# LAN9255ZMX019 device description
Architecture: CORTEX-M4; Family: LAN9255; Series: LAN9255ZMX
Registers are 32-bit, read-write, reset 0x0 unless marked. A register's access mark holds for its fields unless they carry their own. Offsets are from the block's base; [hi:lo] are bit positions; {n}, {i} and the like mark numbered series; 'fields as' and 'values as' point back to an identical list.

## Pinouts (pin number, pad)
TQFP128: 1 OSCO, 2 PB03, 3 PA00, 4 OSCVDD12, 5 PA01, 6 OSCVSS, 7 VDD33, 8 PA02, 9 PA03, 10 PB04, 11 PB05, 12 VDDCR1, 13 REG_EN, 14 CLK25_EN, 15 GNDANA, 16 VDDANA, 17 ERRLED_LEDPOL4, 18 WAIT_ACK, 19 PB06, 20 PB07, 21 RSTN, 22 PB08, 23 PB09, 24 SIO2, 25 PA04, 26 SIO1, 27 PA05, 28 PA06, 29 VDDIO1_L, 30 PA07, 31 GPIO8, 32 GPIO7, 33 PA08, 34 PA09, 35 PA10, 36 PA11, 37 VDDIOB, 38 SIO0, 39 SYNC1_LATCH1, 40 PB10, 41 SPICLK, 42 PB11, 43 PB12, 44 PB13, 45 VDDIO2_L, 46 PB14, 47 PB15, 48 NC, 49 GPIO6, 50 GPIO5, 51 GPIO4, 52 VDDCR2, 53 EEEMULSPI2, 54 GPIO11, 55 GPIO12, 56 GPIO13, 57 GPIO10, 58 GPIO14, 59 GPIO15, 60 VDDIO3_L, 61 PA12, 62 PA13, 63 PA14, 64 PA15, 65 VDDIO1_S, 66 GPIO9, 67 PA16, 68 PA17, 69 PA18, 70 SYNC0_LATCH0, 71 SIO3, 72 GPIO0, 73 PA19, 74 VDDIO5_L, 75 VMARGIN, 76 VDDCR3, 77 PB16, 78 GPIO1, 79 PB17, 80 GPIO2, 81 TESTMODE, 82 EESDA, 83 EESCL, 84 PA20, 85 NC, 86 NC, 87 PA21, 88 IRQ, 89 RUNLED_E2PSIZE, 90 LINKACTLED1_CHIPMODE1, 91 PA22, 92 PA23, 93 PA24, 94 VDDIO4_L, 95 LINKACTLED0_CHIPMODE0, 96 PA25, 97 VDDIO2_S, 98 PB22, 99 PB23, 100 GPIO3, 101 SPICS, 102 VDD33TXRX1, 103 TXNA, 104 TXPA, 105 RXNA, 106 RXPA, 107 PA27, 108 RESET_N, 109 VDDCORE, 110 VDD12TX1, 111 RBIAS, 112 VDD33BIAS, 113 VDD12TX2, 114 VSW, 115 RXPB, 116 RXNB, 117 VDDIO3_S, 118 TXPB, 119 TXNB, 120 PA30, 121 PA31, 122 PB30, 123 PB31, 124 VDD33TXRX2, 125 PB00, 126 PB01, 127 PB02, 128 OSCI

## AC — Analog Comparators
Instances: AC 0x42002000
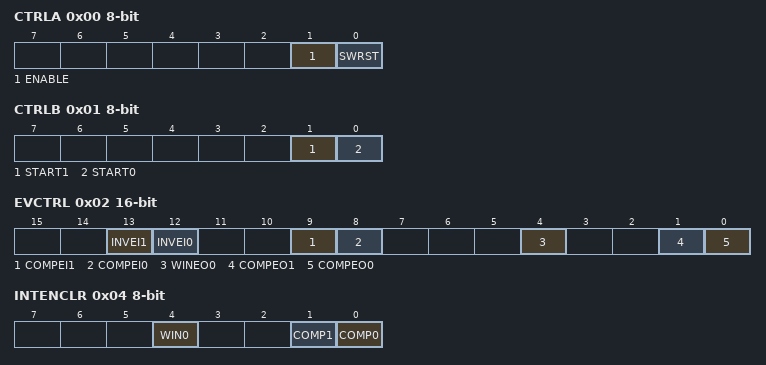
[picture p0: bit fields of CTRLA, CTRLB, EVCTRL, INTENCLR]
0x00 CTRLA 8-bit (WSYNC) — Control A
  [1] ENABLE
  [0] SWRST — Software Reset
0x01 CTRLB 8-bit wo — Control B
  [1] START1 — Comparator 1 Start Comparison
  [0] START0 — Comparator 0 Start Comparison
0x02 EVCTRL 16-bit — Event Control
  [13] INVEI1 — Comparator 1 Input Event Invert Enable
  [12] INVEI0 — Comparator 0 Input Event Invert Enable
  [9] COMPEI1 — Comparator 1 Event Input Enable
  [8] COMPEI0 — Comparator 0 Event Input Enable
  [4] WINEO0 — Window 0 Event Output Enable
  [1] COMPEO1 — Comparator 1 Event Output Enable
  [0] COMPEO0 — Comparator 0 Event Output Enable
0x04 INTENCLR 8-bit (atomic clear) — Interrupt Enable Clear
  [4] WIN0 — Window 0 Interrupt Enable
  [1] COMP1 — Comparator 1 Interrupt Enable
  [0] COMP0 — Comparator 0 Interrupt Enable
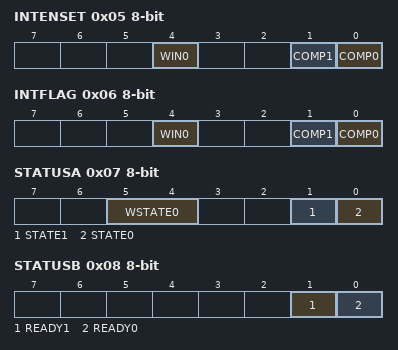
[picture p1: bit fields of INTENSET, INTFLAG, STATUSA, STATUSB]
0x05 INTENSET 8-bit (atomic set) — Interrupt Enable Set
  fields as INTENCLR
0x06 INTFLAG 8-bit (atomic clear) — Interrupt Flag Status and Clear
  [4] WIN0 — Window 0
  [1] COMP1 — Comparator 1
  [0] COMP0 — Comparator 0
0x07 STATUSA 8-bit ro
  [5:4] WSTATE0 — Window 0 Current State
    0=ABOVE (Signal is above window); 1=INSIDE (Signal is inside window); 2=BELOW (Signal is below window)
  [1] STATE1 — Comparator 1 Current State
  [0] STATE0 — Comparator 0 Current State
0x08 STATUSB 8-bit ro
  [1] READY1 — Comparator 1 Ready
  [0] READY0 — Comparator 0 Ready
0x09 DBGCTRL 8-bit — Debug Control
  [0] DBGRUN — Debug Run
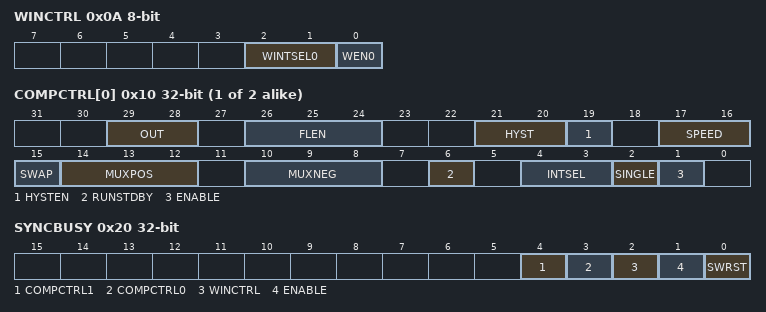
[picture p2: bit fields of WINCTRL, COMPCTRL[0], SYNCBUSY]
0x0A WINCTRL 8-bit (WSYNC) — Window Control
  [2:1] WINTSEL0 — Window 0 Interrupt Selection
    0=ABOVE (Interrupt on signal above window); 1=INSIDE (Interrupt on signal inside window); 2=BELOW (Interrupt on signal below window); 3=OUTSIDE (Interrupt on signal outside window)
  [0] WEN0 — Window 0 Mode Enable
{0xC+i} SCALER[{i}] (i=0..1) 8-bit — Scaler n
  [5:0] VALUE — Scaler Value
{0x10+4i} COMPCTRL[{i}] (i=0..1) — Comparator Control n
  [29:28] OUT — Output
    0=OFF (The output of COMPn is not routed to the COMPn I/O port); 1=ASYNC (The asynchronous output of COMPn is routed to the COMPn I/O port); 2=SYNC (The synchronous output (including filtering) of COMPn is routed to the COMPn I/O port)
  [26:24] FLEN — Filter Length
    0=OFF (No filtering); 1=MAJ3 (3-bit majority function (2 of 3)); 2=MAJ5 (5-bit majority function (3 of 5))
  [21:20] HYST — Hysteresis Level
    0=50mV; 1=100mV; 2=150mV
  [19] HYSTEN — Hysteresis Enable
  [17:16] SPEED — Speed Selection
    3=HIGH (High speed)
  [15] SWAP — Swap Inputs and Invert
  [14:12] MUXPOS — Positive Input Mux Selection
    {v}=PIN{v} (I/O pin {v}) (v=0..3); 4=VSCALE (VDD Scaler)
  [10:8] MUXNEG — Negative Input Mux Selection
    {v}=PIN{v} (I/O pin {v}) (v=0..3); 4=GND (Ground); 5=VSCALE (VDD scaler); 6=BANDGAP (Internal bandgap voltage); 7=DAC (DAC output)
  [6] RUNSTDBY — Run in Standby
  [4:3] INTSEL — Interrupt Selection
    0=TOGGLE (Interrupt on comparator output toggle); 1=RISING (Interrupt on comparator output rising); 2=FALLING (Interrupt on comparator output falling); 3=EOC (Interrupt on end of comparison (single-shot mode only))
  [2] SINGLE — Single-Shot Mode
  [1] ENABLE
0x20 SYNCBUSY ro — Synchronization Busy
  [4] COMPCTRL1 — COMPCTRL 1 Synchronization Busy
  [3] COMPCTRL0 — COMPCTRL 0 Synchronization Busy
  [2] WINCTRL — WINCTRL Synchronization Busy
  [1] ENABLE — Enable Synchronization Busy
  [0] SWRST — Software Reset Synchronization Busy
0x24 CALIB 16-bit reset 0x101 — Calibration
  [1:0] BIAS0 — COMP0/1 Bias Scaling

## Notices in the file
Copyright (c) 2018 Microchip Technology Inc.
SPDX-License-Identifier: Apache-2.0
Licensed under the Apache License, Version 2.0 (the "License");
you may not use this file except in compliance with the License.
You may obtain a copy of the License at
http://www.apache.org/licenses/LICENSE-2.0
Unless required by applicable law or agreed to in writing, software
distributed under the License is distributed on an "AS IS" BASIS,
WITHOUT WARRANTIES OR CONDITIONS OF ANY KIND, either express or implied.
See the License for the specific language governing permissions and
limitations under the License.
